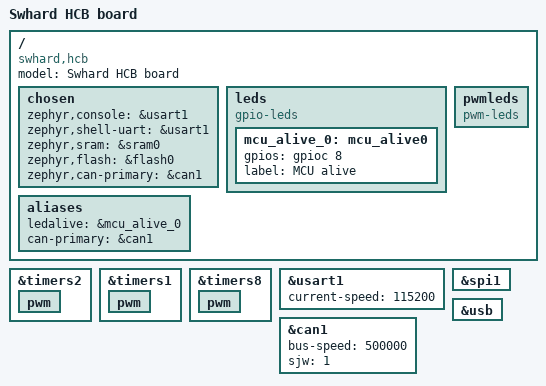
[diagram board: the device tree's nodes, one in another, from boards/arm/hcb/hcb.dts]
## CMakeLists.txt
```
# Boilerplate code, which pulls in the Zephyr build system.
cmake_minimum_required(VERSION 3.13.1)

set(BOARD_ROOT ${CMAKE_CURRENT_LIST_DIR})
set(BOARD hcb)

include($ENV{ZEPHYR_BASE}/cmake/app/boilerplate.cmake NO_POLICY_SCOPE)
project(HCB VERSION 0.1 LANGUAGES C)
message(STATUS "HCB Version: ${PROJECT_VERSION} ") 

set (COMMON_PATH ${CMAKE_CURRENT_LIST_DIR}/common)
include(${COMMON_PATH}/proto.cmake)

add_library(project_options INTERFACE)
target_compile_options(project_options INTERFACE -fdiagnostics-color=always -Wno-sign-compare -Wall -Wextra -Wnull-dereference -Wmisleading-indentation -Wduplicated-cond -Wno-unused-parameter -Werror=return-type)
target_compile_definitions(project_options  INTERFACE "HCB_FW_VERSION=\"${PROJECT_VERSION}\"")

set(CMAKE_EXPORT_COMPILE_COMMANDS ON)
# Add your source file to the "app" target. This must come after
# the boilerplate code, which defines the target.

set(APP_SRC 
src/main.c 
src/adc_subsystem.h src/adc_subsystem.c
src/usb_hcb_subsystem.h src/usb_hcb_subsystem.c
src/can_subsystem.h src/can_subsystem.c
)

target_sources(app PRIVATE ${APP_SRC})

target_link_libraries(app PUBLIC hcb_proto project_options)
```

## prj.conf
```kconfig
CONFIG_PRINTK=y
CONFIG_SHELL=y
CONFIG_KERNEL_SHELL=y
CONFIG_INIT_STACKS=y
CONFIG_BOOT_BANNER=y
CONFIG_DEVICE_SHELL=y
CONFIG_SHELL_PROMPT_UART="hcb:~$ "
CONFIG_SHELL_STACK_SIZE=1024
CONFIG_SHELL_HISTORY_BUFFER=128
CONFIG_PWM_SHELL=y
CONFIG_HEAP_MEM_POOL_SIZE=512
CONFIG_ENABLE_HID_INT_OUT_EP=y
CONFIG_USB_HID_REPORTS=2
CONFIG_HID_INTERRUPT_EP_MPS=64
CONFIG_USB_HID_POLL_INTERVAL_MS=1
CONFIG_REBOOT=y
```

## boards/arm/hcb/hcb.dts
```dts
/*
 * Copyright (c) 2017 I-SENSE group of ICCS
 *
 * SPDX-License-Identifier: Apache-2.0
 */

/dts-v1/;
#include <st/f3/stm32f303Xc.dtsi>

/ {
	model = "Swhard HCB board";
	compatible = "swhard,hcb", "st,stm32f303";

	chosen {
		zephyr,console = &usart1;
		zephyr,shell-uart = &usart1;
		zephyr,sram = &sram0;
		zephyr,flash = &flash0;
		zephyr,can-primary = &can1;
	};

	leds {
		compatible = "gpio-leds";
		mcu_alive_0: mcu_alive0 {
			gpios = <&gpioc 8 GPIO_ACTIVE_HIGH>;
			label = "MCU alive";
		};
	};

	pwmleds {
		compatible = "pwm-leds";	


	};

	aliases {
		ledalive = &mcu_alive_0;
		
		can-primary = &can1;
	};

};

&timers2 {
	status = "okay";

	pwm {
		status = "okay";
	};
};

// TIM -> PWM_DEVICE
&timers1 {
	status = "okay";

	pwm {
		status = "okay";
	};
};

// TIM -> PWM_DEVICE
&timers8 {
	status = "okay";

	pwm {
		status = "okay";
	};
};


&usart1 {
	current-speed = <115200>;
	status = "okay";
};

&spi1 {
	status = "okay";
};

&usb {
	status = "ok";
};

&can1 {
	status = "ok";
	bus-speed = <500000>;
	sjw = <1>;
};
```

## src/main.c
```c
// Set the log level to INFO
#define LOG_LEVEL LOG_LEVEL_INF
#include <logging/log.h>

// Register the module as "p" with INFO log level
LOG_MODULE_REGISTER(p, LOG_LEVEL_INF);

#include "adc_subsystem.h"

#include <drivers/can.h>
#include <drivers/gpio.h>
#include <zephyr.h>
#include <sys/printk.h>
#include <device.h>
#include <drivers/pwm.h>

#include "usb_hcb_subsystem.h"

// Define GPIO for LED
#define LED_PORT "GPIOC"
#define LED_PIN	 8

// Define minimum and maximum period for PWM
#define MIN_PERIOD_USEC (USEC_PER_SEC / 64U)
#define MAX_PERIOD_USEC USEC_PER_SEC
#define FILTER_LEN 8

// PID Controller Constants
#define Kp 0.3
#define Ki 0.7

#define K1 (Kp + Ki)
#define K2 -Kp

// Define mutexes for ADC and PID
K_MUTEX_DEFINE(adcMutex);
K_MUTEX_DEFINE(pidMutex);

// Arrays to store ADC values and set points
uint16_t adc_vals[24];
uint16_t set_points[8];
/**
 * @brief Mapping of ADC channels to axis
 * 
 * This array maps ADC channels to their corresponding axis.
 * Each row represents an ADC, and each column represents a channel.
 * The values indicate the order in which the channels are read for each ADC.
 * For example, ch2axis[0][0] represents the first channel to read for ADC 1.
 */
static const uint8_t ch2axis[AD_MAX][ADS868_CH_MAX] = {{1,2,3,4,5,6,7,0},{1,2,3,4,5,6,7,0},{1,2,3,4,5,6,7,0}};

/**
 * @brief Array indicating enabled ADC channels
 * 
 * This array indicates whether each ADC is enabled (1) or disabled (0).
 * Each element corresponds to an ADC, with 1 indicating enabled and 0 disabled.
 */
static const uint8_t enabled_adc[AD_MAX] = {1,0,1};

/**
 * @brief Function to acquire ADC values
 * 
 * This function acquires ADC values for enabled channels.
 * It uses a static array to filter ADC values over multiple samples.
 * Mutex is used to ensure thread safety.
 */
void acquire_adc()
{
	// Static variables for filtering ADC values
	static uint16_t internal_adc_vals[FILTER_LEN][24]; // Lots of SPI transactions
	static int filter_idx = 0;

	// Iterate through ADCs and channels to acquire values
	for (adc_t ad = AD_1; ad < AD_MAX; ++ad){
		if(enabled_adc[ad] == 1){
			for (channel_t ch = ADS868_CH_1; ch < ADS868_CH_MAX; ++ch) {
				int idx = (ad * 8) + ch2axis[ad][ch];
				internal_adc_vals[filter_idx][idx] = ads8668_acquire(ad, ch);
			}
		}
	}
	// Update filter index
	filter_idx++;
	if (filter_idx >= FILTER_LEN)
		filter_idx = 0;

	// Apply filter and update adc_vals array
	k_mutex_lock(&adcMutex, K_FOREVER);
	//only first ADC for the pression and third fot the current
	for (int i  = 0; i < 24 ; i++){
		int acc = 0;
		if(i < 8 || i > 15){
			for( int j = 0 ; j < FILTER_LEN ; j ++){	
				acc += internal_adc_vals[j][i]; 
				
			}
		adc_vals[i] = acc/ FILTER_LEN;
		}
	}
	k_mutex_unlock(&adcMutex);
}


/**
 * @brief Structure for PID Controller
 * 
 * This structure holds the variables required for the PID controller.
 */
typedef struct pid{
    float n_1_u;        // Previous control signal
    float n_1_error;    // Previous error
    float error;        // Current error
    float control;      // Current control signal
}pid;


/**
 * @brief PID Controller Function
 * 
 * This function implements the PID controller algorithm.
 * It calculates the control signal based on current errors and previous control signals.
 */

void PID_Controller(pid *pid_current){
	
	// Local variables for setpoints and ADC values
	uint16_t local_setpoints[8];
	uint16_t local_adcvals[24];
	
	// Copy setpoints and ADC values into local variables
	k_mutex_lock(&adcMutex, K_FOREVER);
	memcpy(local_setpoints,set_points,sizeof(set_points));
	memcpy(local_adcvals,adc_vals,sizeof(adc_vals));
	k_mutex_unlock(&adcMutex);
    
	// Iterate through ADC channels
	for(int i = 0; i < ADS868_CH_MAX; i++) {

		// Check if setpoint is below threshold
		if(local_setpoints[i] < 410) {
			pid_current[i].control = 0;
			continue;
		}
		
		//General sensor , constant value of on/off
		if(i == 6) pid_current[i].control = 5000;
		
		else{
			// Calculate error and control signal
			pid_current[i].error = local_setpoints[i] - local_adcvals[i];
			pid_current[i].control = pid_current[i].n_1_u + K1*pid_current[i].error + K2*pid_current[i].n_1_error;

			//Limite dei PWM settato 3000
			if(pid_current[i].control > 3000){
				pid_current[i].control = 3000;
			}
			if(pid_current[i].control <= 0){
				pid_current[i].control = 0;
			}
			// Update previous control signal and error
			pid_current[i].n_1_u = pid_current[i].control;
			pid_current[i].n_1_error = pid_current[i].error;
		}
		
	}

}


/**
 * @brief Set the default ADC range
 * 
 * This function sets the default range for all ADC channels.
 * It iterates through each ADC and channel, setting the range to 1.25V.
 */

void default_adc_range()
{
	for (adc_t ad = AD_1; ad < AD_MAX; ++ad) {
		for (channel_t ch = ADS868_CH_1; ch < ADS868_CH_MAX; ++ch) {
			ads8668_set_range(ad, ch, ADS868_RANGE_1_25_M);
		}
	}
}

/**
 * @brief Get the ADC values
 * 
 * This function copies ADC values to the destination buffer.
 * It locks the ADC mutex to ensure thread safety while copying.
 * 
 * @param dst Destination buffer to store ADC values
 */

void get_adc_values(uint16_t *dst)
{
	k_mutex_lock(&adcMutex, K_FOREVER);
	memcpy(dst, adc_vals, sizeof(adc_vals));
	k_mutex_unlock(&adcMutex);
}

// Declaration of static variables to store PWM devices
static const struct device *pwm_dev_1;
static const struct device *pwm_dev_2;
static const struct device *pwm_dev_8;

// Enumeration for PWM channels
typedef enum pwm_t { PWM_1, PWM_2, PWM_8, PWM_MAX } pwm_t;

// Function to get the PWM device based on the PWM channel
const struct device *get_pwm_dev(pwm_t pwm)
{
	switch (pwm) {
	case PWM_1:
		return pwm_dev_1;
	case PWM_2:
		return pwm_dev_2;
	case PWM_8:
		return pwm_dev_8;
	case PWM_MAX:
		return NULL;
	}

	return NULL;
}

// Structure to hold PWM descriptor
typedef struct pwm_descriptor_t {
	pwm_t pwm;
	uint32_t channel;
	uint32_t period;
} pwm_descriptor_t;

// Maximum number of PWM channels
#define PWM_MAX_CHANNELS 8

// PWM descriptors initialization
const pwm_descriptor_t pwm_descriptor[PWM_MAX_CHANNELS] = {
	{ PWM_2, 1, 8333 }, // SA1
	{ PWM_2, 2, 8333 }, // SA2
	{ PWM_1, 2, 8333 }, // SB1
	{ PWM_1, 1, 8333 }, // SB2
	{ PWM_8, 2, 8333 }, // SC1
	{ PWM_8, 1, 8333 }, // SC2
	{ PWM_2, 3, 8333 }, // SD1 -- 
	{ PWM_2, 4, 8333 }, // SD2
};

/**
 * @brief Initialize PWM devices
 * 
 * This function initializes the PWM devices by getting their bindings.
 * It assigns the device pointers to static variables for later use.
 */
void pwm_init()
{
	pwm_dev_1 = device_get_binding("PWM_1");
	pwm_dev_2 = device_get_binding("PWM_2");
	pwm_dev_8 = device_get_binding("PWM_8");
}

/**
 * @brief Set PWM ranges
 * 
 * This function sets the PWM ranges based on PID controller outputs.
 * It iterates through the PWM channels and sets their duty cycles accordingly.
 * Additionally, it updates the ADC values corresponding to PWM channels.
 * 
 * @param pid_current Array of PID controller structures
 */
void set_pwm_ranges(pid *pid_current)
{
	for (int i = 0; i < PWM_MAX_CHANNELS; ++i) {
		pwm_pin_set_usec(get_pwm_dev(pwm_descriptor[i].pwm), pwm_descriptor[i].channel, pwm_descriptor[i].period, (uint32_t) pid_current[i].control, 0);
		adc_vals[i+ 8] = (uint16_t)pid_current[i].control;
	}
}

/**
 * @brief Convert value from bar to bananas
 * 
 * This function converts a value from the bar scale to the bananas scale.
 * 
 * @param val Value in the bar scale
 * @return Converted value in the bananas scale
 */
uint16_t fromBartoBananas(uint32_t val){
	return (uint16_t) ((val*1600)/350) + 400;
}

/**
 * @brief Set setpoints
 * 
 * This function sets the setpoints for the PID controller.
 * It converts the values from the bar scale to the bananas scale and updates the set_points array.
 * 
 * @param vals Array of setpoints in the bar scale
 */
void set_setpoints(uint32_t *vals){
	k_mutex_lock(&adcMutex, K_FOREVER);
	for(int i = 0; i < ADS868_CH_MAX ; i++){
		set_points[i] = fromBartoBananas(vals[i]);
	}
	k_mutex_unlock(&adcMutex);
}

/**
 * @brief PID current thread
 * 
 * This thread continuously runs the PID controller algorithm.
 * It locks the PID mutex, executes the controller, sets PWM ranges, and unlocks the mutex.
 * It then waits for a specified delay before repeating the process.
 */
void pid_current_thread(){
	uint32_t target = k_uptime_get_32();
	uint32_t delay = 0;
	pid pid_current[8];
	while (1) {	
		// Current control loop and set pwm
		k_mutex_lock(&pidMutex, K_FOREVER);
		PID_Controller(pid_current);
		set_pwm_ranges(pid_current);
		k_mutex_unlock(&pidMutex);
		do {
			target += 10;
			delay = target - k_uptime_get_32();
		} while (delay > 10);
		k_sleep(K_MSEC(delay));
	}

}

/**
 * @brief Main function
 * 
 * This function is the entry point of the application.
 * It initializes necessary components, such as ADC, PWM, USB transport, and default ADC range.
 * It then enters an infinite loop where it continuously acquires ADC values, sets LED status, and sleeps for a specified delay.
 */
void main(void)
{
	const struct device *alive_dev = device_get_binding(LED_PORT);
	gpio_pin_configure(alive_dev, LED_PIN, GPIO_OUTPUT_ACTIVE);

	printk("\nHCB V:%s \n", HCB_FW_VERSION);

	adc_init();
	pwm_init();
	usb_transport_init();
	default_adc_range();

	acquire_adc();

	uint32_t target = k_uptime_get_32();
	uint32_t delay = 0;
	while (1) {	
		acquire_adc();
		do {
			target += 5;
			delay = target - k_uptime_get_32();
		} while (delay > 5);
		k_sleep(K_MSEC(delay));
		gpio_pin_set(alive_dev, LED_PIN, 1);
	}
}

/* Definition of thread stack size */
#define STACKSIZE 1024
/* scheduling priority used by each thread */
#define PRIORITY 7

/* Thread definitions */
K_THREAD_DEFINE(send_id, STACKSIZE, usb_transport_thread, NULL, NULL, NULL,
		PRIORITY, 0, 10);

K_THREAD_DEFINE(unsolicited_id, STACKSIZE, usb_unsolicited_stuff, NULL, NULL,
		NULL, PRIORITY, 0, 10);

K_THREAD_DEFINE(pid_thread, STACKSIZE, pid_current_thread, NULL, NULL,
		NULL, PRIORITY, 0, 10);
```

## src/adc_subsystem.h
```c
// Stuff to control the ADC - for now just user space
#ifndef _ADC_SUBSYSTEM_H_
#define _ADC_SUBSYSTEM_H_

#include <stdint.h>

typedef enum adc_t { AD_1, AD_2, AD_3, AD_MAX } adc_t;

typedef enum channel_t {
	ADS868_CH_1=0,
	ADS868_CH_2,
	ADS868_CH_3,
	ADS868_CH_4,
	ADS868_CH_5,
	ADS868_CH_6,
	ADS868_CH_7,
	ADS868_CH_8,
	ADS868_CH_MAX
} channel_t;

typedef enum ch_range_t {
	ADS868_RANGE_2_50_B = 0,
	ADS868_RANGE_1_25_B = 1,
	ADS868_RANGE_0_62_B = 2,
	ADS868_RANGE_0_31_B = 3,
	ADS868_RANGE_0_15_B = 11,
	ADS868_RANGE_2_50_M = 5,
	ADS868_RANGE_1_25_M = 6,
	ADS868_RANGE_0_62_M = 7,
	ADS868_RANGE_0_31_M = 15,
} ch_range_t;

void adc_init();
void adc_hw_reset();

// ADS8668 commands
int ads8668_reset_command(enum adc_t adc);
int ads8668_standby_command(enum adc_t adc);

int ads8668_acquire(adc_t adc, uint8_t ch);
int ads8668_set_range(adc_t adc, uint8_t ch, ch_range_t ch_range);

uint8_t ads8668_read_reg(adc_t adc, uint8_t reg);
int ads8668_write_reg(adc_t adc, uint8_t reg, uint8_t data);

// MAX5714 command
typedef enum max5714_output_t {
	MAX5714_DAC_A = 0x00,
	MAX5714_DAC_B = 0x01,
	MAX5714_DAC_C = 0x02,
	MAX5714_DAC_D = 0x03,
	MAX5714_DAC_ALL = 0x0f,
} max5714_output_t;

typedef enum max5714_cmd_mode_t {
	MAX5714_CMD_CODEn = 0x00,
	MAX5714_CMD_LOADn = 0x10,
	MAX5714_CMD_CODEn_LOAD_ALL = 0x20,
	MAX5714_CMD_CODEn_LOADn = 0x30,
} max5714_cmd_mode_t;

int max5714_set_value(max5714_cmd_mode_t mode, max5714_output_t output,
		      int value);
int max5714_clear();
int max5714_reset();

#endif // _ADC_SUBSYSTEM_H_
```

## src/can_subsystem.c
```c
#include "can_subsystem.h"

#include <zephyr.h>
#include <kernel.h>
#include <sys/printk.h>
#include <device.h>
#include <drivers/can.h>
#include <drivers/gpio.h>
#include <sys/byteorder.h>

// Define the stack size and priority for the receiving thread
#define RX_THREAD_STACK_SIZE	     512
#define RX_THREAD_PRIORITY	     2

// Define the stack size and priority for the state polling thread
#define STATE_POLL_THREAD_STACK_SIZE 512
#define STATE_POLL_THREAD_PRIORITY   2

// Define message IDs for LED control and counter
#define LED_MSG_ID		     0x10
#define COUNTER_MSG_ID		     0x12345

// Define commands for LED control
#define SET_LED			     1
#define RESET_LED		     0

// Define sleep time
#define SLEEP_TIME		     K_MSEC(250)

// Define the ID for the Fault Tolerance (FT) system
#define FT_ID 0x1b0

// Define a stack for the receive thread with size RX_THREAD_STACK_SIZE
K_THREAD_STACK_DEFINE(rx_thread_stack, RX_THREAD_STACK_SIZE);

// Define a stack for the poll state thread with size STATE_POLL_THREAD_STACK_SIZE
K_THREAD_STACK_DEFINE(poll_state_stack, STATE_POLL_THREAD_STACK_SIZE);

// Declare pointers to devices for CAN and LED GPIO
const struct device *can_dev;
const struct device *led_gpio_dev;

// Declare thread data structures for receive and poll state threads
struct k_thread rx_thread_data;
struct k_thread poll_state_thread_data;

// Declare work structure for receive work
struct zcan_work rx_work;

// Declare work structure for state change work
struct k_work state_change_work;

// Declare an enumeration to represent the current state of the CAN bus
enum can_state current_state;

// Declare a structure to hold the current error counts on the CAN bus
struct can_bus_err_cnt current_err_cnt;

#ifdef CANFESTIVAL_ZEPHYR_DEBUG

// Function to print the contents of a Zephyr CAN frame
static void print_frame(struct zcan_frame *frame)
{
	// Print frame ID, RTR flag, and DLC
	printk("|0x%3x|%s|%d|", frame->id, frame->rtr ? "RTR" : "   ",
	       frame->dlc);
	
    // Iterate through each byte of data in the frame
	for (int i = 0; i < CAN_MAX_DLEN; i++) {
		if (i < frame->dlc) {

			// Print data byte in hexadecimal format
			printk(" 0x%02x", frame->data[i]);
		} else {
			// If data length is less than the maximum, pad with spaces
			printk("     ");
		}
	}
    // End the line
	printk("|\n");
}
#endif

// Callback function invoked upon transmission error interrupt
void tx_irq_callback(uint32_t error_flags, void *arg)
{   
	// Cast arg to a character pointer representing the sender
	char *sender = (char *)arg;
    // If error flags are non-zero, print error details
	if (error_flags) {
		printk("Callback! error-code: %d\nSender: %s\n", error_flags,
		       sender);
	}
}

// Define a mutex for protecting access to force and torque arrays
K_MUTEX_DEFINE(ftMutex);

// Arrays to store force and torque values
static int32_t forces[3];
static int32_t torques[3];

/**
 * @brief Get the adc values object
 * 
 * @param dst   Destination array to store force and torque values
 */
void get_ft_values(int32_t *dst)
{
	// Lock the mutex to prevent concurrent access to force and torque arrays
	k_mutex_lock(&ftMutex, K_FOREVER);

	// Copy force and torque arrays into destination array
	memcpy(dst, forces, sizeof(forces));
	memcpy(dst+3, torques, sizeof(torques));

	// Unlock the mutex to allow other threads to access force and torque arrays
	k_mutex_unlock(&ftMutex);
}

/**
 * @brief Callback function to receive and update force and torque values
 * 
 * @param frame Pointer to the received CAN frame
 * @param unused Unused argument
 */
void receive_change_led(struct zcan_frame *frame, void *unused)
{
	ARG_UNUSED(unused);
    
	// Iterate over the array indices to check if the received frame corresponds to force or torque data
	for (int i = 1; i < 4; ++i)
	{
		// Check if the frame ID matches the expected ID for force or torque data
		if (frame->id == (FT_ID + i)) {

			// Lock the mutex to prevent concurrent access to force and torque arrays
			k_mutex_lock(&ftMutex, K_FOREVER);

			// Extract force and torque values from the received frame and store them in the respective arrays
			uint32_t f = frame->data_32[0];
			forces[i - 1] = (int32_t)__bswap_32(f);
			uint32_t t = frame->data_32[1];
			torques[i - 1] = (int32_t)__bswap_32(t);

			// Unlock the mutex to allow other threads to access force and torque arrays
			k_mutex_unlock(&ftMutex);
		}
	}

// Optional debug printing if CANFESTIVAL_ZEPHYR_DEBUG is defined
#ifdef CANFESTIVAL_ZEPHYR_DEBUG
	printk(" CAN_RECEIVE: ");
	print_frame(frame);
#endif
}

/**
 * @brief Converts a CAN state enum value to its string representation.
 * 
 * @param state The CAN state enum value to convert.
 * @return A string representation of the CAN state.
 */
char *state_to_str(enum can_state state)
{
	switch (state) {
	case CAN_ERROR_ACTIVE:
		return "error-active";
	case CAN_ERROR_PASSIVE:
		return "error-passive";
	case CAN_BUS_OFF:
		return "bus-off";
	default:
		return "unknown";
	}
}

/**
 * @brief Thread function to continuously poll the CAN bus state and error counts.
 * 
 * @param unused1 Unused parameter (required by Zephyr thread API).
 * @param unused2 Unused parameter (required by Zephyr thread API).
 * @param unused3 Unused parameter (required by Zephyr thread API).
 */
void poll_state_thread(void *unused1, void *unused2, void *unused3)
{   
	// Initialize error count structures
	struct can_bus_err_cnt err_cnt = { 0, 0 };
	struct can_bus_err_cnt err_cnt_prev = { 0, 0 };

	// Initialize previous state to error active
	enum can_state state_prev = CAN_ERROR_ACTIVE;

	// Variable to hold current CAN state
	enum can_state state;
    
	// Continuous loop to poll CAN state and error counts
	while (1) {

		// Get current CAN state and error counts
		state = can_get_state(can_dev, &err_cnt);

		// Check if there's a change in state or error counts
		if (err_cnt.tx_err_cnt != err_cnt_prev.tx_err_cnt ||
		    err_cnt.rx_err_cnt != err_cnt_prev.rx_err_cnt ||
		    state_prev != state) {
			// Update previous error counts and state
			err_cnt_prev.tx_err_cnt = err_cnt.tx_err_cnt;
			err_cnt_prev.rx_err_cnt = err_cnt.rx_err_cnt;
			state_prev = state;

			// Print current state and error counts
			printk("state: %s\n"
			       "rx error count: %d\n"
			       "tx error count: %d\n",
			       state_to_str(state), err_cnt.rx_err_cnt,
			       err_cnt.tx_err_cnt);
		} else {

			// Sleep for a short duration to avoid continuous polling
			k_sleep(K_MSEC(100));
		}
	}
}

/**
 * @brief Handler function for state change work.
 * 
 * @param work Pointer to the work item.
 */
void state_change_work_handler(struct k_work *work)
{
	// Print current state and error counts
	printk("State Change ISR\nstate: %s\n"
	       "rx error count: %d\n"
	       "tx error count: %d\n",
	       state_to_str(current_state), current_err_cnt.rx_err_cnt,
	       current_err_cnt.tx_err_cnt);

// Perform recovery from bus-off state if auto recovery is not enabled
#ifndef CONFIG_CAN_AUTO_BUS_OFF_RECOVERY
	if (current_state == CAN_BUS_OFF) {
		printk("Recover from bus-off\n");

        // Attempt to recover from bus-off state
		if (can_recover(can_dev, K_MSEC(100) != 0)) {
			printk("Recovery timed out\n");
		}
	}
#endif /* CONFIG_CAN_AUTO_BUS_OFF_RECOVERY */
}

/**
 * @brief Interrupt service routine for CAN state change.
 * 
 * @param state The new CAN state.
 * @param err_cnt Error counts for the CAN bus.
 */
void state_change_isr(enum can_state state, struct can_bus_err_cnt err_cnt)
{
	// Update current state and error counts
	current_state = state;
	current_err_cnt = err_cnt;

	// Submit state change work for handling
	k_work_submit(&state_change_work);
}

/**
 * @brief Main thread for handling CAN communication and LED change requests.
 * 
 * @param _1 Unused parameter (required by Zephyr thread API).
 * @param _2 Unused parameter (required by Zephyr thread API).
 * @param _3 Unused parameter (required by Zephyr thread API).
 */
void main_can_ati_thread(void *_1, void *_2, void *_3)
{
	// Define a CAN filter for LED change messages
	static const struct zcan_filter my_filter = {
		.id_type = CAN_STANDARD_IDENTIFIER,
		.rtr = CAN_DATAFRAME,
		.id = 0x1,
		.rtr_mask = 0,
		.id_mask = 0x0
	};
    // Define a CAN frame for requesting LED changes
	struct zcan_frame req_long_data_frame = {
		.id_type = CAN_STANDARD_IDENTIFIER,
		.rtr = CAN_DATAFRAME,
		.id = FT_ID,
		.dlc = 1
	};
    // Variable to toggle LED change data
    uint8_t toggle = 1;
    
    // Counter for LED change requests
    uint16_t counter = 0;
    
    // Thread IDs for polling state and receiving CAN frames
    k_tid_t rx_tid, get_state_tid;
    
    // Return value for function calls
    int ret;

    // Get the CAN device
    can_dev = device_get_binding(DT_CHOSEN_ZEPHYR_CAN_PRIMARY_LABEL);

    // Check if CAN device is found
    if (!can_dev) {
        printk("CAN: Device driver not found.\n");
        return;
    }

    // Initialize state change work handler
    k_work_init(&state_change_work, state_change_work_handler);

    // Attach a filter for receiving LED change messages
    ret = can_attach_workq(can_dev, &k_sys_work_q, &rx_work,
                           receive_change_led, NULL, &my_filter);
    if (ret == CAN_NO_FREE_FILTER) {
        printk("Error, no filter available!\n");
        return;
    }

    // Create a thread for polling CAN bus state
	printk("Change LED filter ID: %d\n", ret);
	get_state_tid =
		k_thread_create(&poll_state_thread_data, poll_state_stack,
				K_THREAD_STACK_SIZEOF(poll_state_stack),
				poll_state_thread, NULL, NULL, NULL,
				STATE_POLL_THREAD_PRIORITY, 0, K_NO_WAIT);
	if (!get_state_tid) {
		printk("ERROR spawning poll_state_thread\n");
	}

    // Register CAN state change ISR
    can_register_state_change_isr(can_dev, state_change_isr);

    // Print initialization completion message
    printk("Finished init.\n");

    // Main loop for sending LED change requests
    while (1) {
        // Set LED change request data
        req_long_data_frame.data[0] = 0x01;
        
        // Send LED change request
        can_send(can_dev, &req_long_data_frame, K_FOREVER,
                 tx_irq_callback, "LED change");
        
        // Sleep for a defined duration
        k_sleep(SLEEP_TIME);
    }
}

// Thread Definition

// Define stack size and priority for main CAN ATI thread
#define CANATI_STACK_SIZE 512
#define CANATI_PRIORITY	  5

// Define main CAN ATI thread
K_THREAD_DEFINE(CANATI, CANATI_STACK_SIZE, main_can_ati_thread, NULL, NULL,
                NULL, CANATI_PRIORITY, 0, 0);
```

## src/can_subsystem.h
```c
#ifndef CAN_SUBSYSTEM_H_
#define CAN_SUBSYSTEM_H_



#endif // CAN_SUBSYSTEM_H_
```

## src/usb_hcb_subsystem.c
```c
/*
 * Copyright (c) 2019 Intel Corporation
 *
 * SPDX-License-Identifier: Apache-2.0
 */

#define LOG_LEVEL LOG_LEVEL_INF
#include <logging/log.h>

LOG_MODULE_REGISTER(usb_transport, LOG_LEVEL_INF);

#include <zephyr.h>

#include <usb/usb_device.h>
#include <usb/class/usb_hid.h>
#include <drivers/gpio.h>
#include <sys/crc.h>

// SHELL STUFF
#include <shell/shell.h>
#include <stdlib.h>

#include "usb_hcb_subsystem.h"

typedef struct msg_data_t {
	void *fifo_reserved; /* 1st word reserved for use by fifo */
	hcb_protocol_t msg;
} msg_data_t;

// FIFO DEFINITION
K_FIFO_DEFINE(trasmission_fifo);
// SEMAPHORE
K_SEM_DEFINE(my_sem, 0, 1);

/* callback function list */
static void usb_transport_host_ready(const struct device *dev);

void int_out_ready_cb(const struct device *dev);

int usb_transport_send_reply(hcb_protocol_t *proto);

static const struct hid_ops usb_transport_callbacks = {
	.int_in_ready = usb_transport_host_ready,
	.int_out_ready = int_out_ready_cb,
};

/* create an HID report descriptor with input and output reports */
static const uint8_t usb_transport_hid_report_desc[] = {
	0x06, 0x00, 0xFF, // (GLOBAL) USAGE_PAGE         0xFF00 Vendor-defined
	0x09, 0x01, //   (LOCAL)  USAGE              0xFF000001
	0xA1, 0x01, // (MAIN)   COLLECTION         0x01 Application (Usage=0x0: Page=, Usage=, Type=) <-- Warning: USAGE type should be CA (Application)
	0x15, 0x00, //   (GLOBAL) LOGICAL_MINIMUM    0x00 (0) <-- Redundant: LOGICAL_MINIMUM is already 0
	0x26, 0xFF, 0x00, //   (GLOBAL) LOGICAL_MAXIMUM    0x00FF (255)
	0x75, 0x08, //   (GLOBAL) REPORT_SIZE        0x08 (8) Number of bits per field
	0x85, 0x01, //   (GLOBAL) REPORT_ID          0x01 (1)
	0x95, 0x50, //   (GLOBAL) REPORT_COUNT       0x40 (64) Number of fields
	0x09, 0x01, //   (LOCAL)  USAGE              0xFF000001
	0x81, 0x02, //   (MAIN)   INPUT              0x00000002 (64 fields x 8 bits) 0=Data 1=Variable 0=Absolute 0=NoWrap 0=Linear 0=PrefState 0=NoNull 0=NonVolatile 0=Bitmap
	0x85, 0x02, //   (GLOBAL) REPORT_ID          0x02 (2)
	0x09, 0x01, //   (LOCAL)  USAGE              0xFF000001
	0x95, 0x20, //   (GLOBAL) REPORT_COUNT       0x20 (32) Number of fields
	0x91, 0x02, //   (MAIN)   OUTPUT             0x00000002 (64 fields x 8 bits) 0=Data 1=Variable 0=Absolute 0=NoWrap 0=Linear 0=PrefState 0=NoNull 0=NonVolatile 0=Bitmap
	0xC0, // (MAIN)   END_COLLECTION     Application
};

static const struct device *hid_device;
static hcb_protocol_t hb1 = {};

// PROTOTYPES
int usb_transfer_msg(hcb_protocol_t *proto);

//
int send_msg_hello_reply()
{
	hb1.header.report_id = HCB_REPORT_ID_IN_REPLY;
	hb1.header.message_id = HCB_ID_HELLO_REPLY;
	hb1.header.crc = 0;
	hb1.header.byte_count = sizeof(hcb_msg_hello_reply_t);

	hb1.hello_reply.ver = HCB_PROTOCOL_VER;

	hb1.header.crc = crc8_ccitt(0x0, hb1.raw, hb1.header.byte_count);

	LOG_ERR("send_msg_hello_reply !");

	int ret = usb_transport_send_reply(&hb1);

	if (ret) {
		LOG_ERR("send_msg_hello_reply error %d", ret);
	}
	return ret;
}

int send_msg_adc()
{
	hb1.header.report_id = HCB_REPORT_ID_IN_REPLY;
	hb1.header.message_id = HCB_ID_ADC;
	hb1.header.crc = 0;
	hb1.header.byte_count = sizeof(hcb_msg_adc_t);

	for (int i = 0; i < 24; ++i) {
		hb1.adc.val[i] = i;
	}

	hb1.header.crc = crc8_ccitt(0x0, hb1.raw, hb1.header.byte_count);

	int ret = usb_transport_send_reply(&hb1);
	if (ret) {
		LOG_ERR("send_msg_adc error %d", ret);
	}

	return ret;
}

int send_adc_values()
{
	hb1.header.report_id = HCB_REPORT_ID_IN_UNSOLICITED;
	hb1.header.message_id = HCB_ID_ADC;
	hb1.header.crc = 0;
	hb1.header.byte_count = sizeof(hcb_msg_adc_t);

	get_adc_values(hb1.adc.val);

	hb1.header.crc = crc8_ccitt(0x0, hb1.raw, hb1.header.byte_count);

	int ret = usb_transport_send_reply(&hb1);
	return ret;
}

static void status_cb(enum usb_dc_status_code status, const uint8_t *param)
{
	switch (status) {
	case USB_DC_CONFIGURED:
		LOG_INF(" #USB_DC_CONFIGURED");
		k_sem_give(&my_sem);
		break;
	default:
		LOG_ERR("status CB %u", status);
		break;
	}
}

int send_ati_values()
{
	hb1.header.report_id = HCB_REPORT_ID_IN_UNSOLICITED;
	hb1.header.message_id = HCB_ID_FT;
	hb1.header.crc = 0;
	hb1.header.byte_count = sizeof(hcb_msg_adc_t);

	get_ft_values(hb1.ft.val);

	hb1.header.crc = crc8_ccitt(0x0, hb1.raw, hb1.header.byte_count);

	int ret = usb_transport_send_reply(&hb1);
	return ret;
}

/**
 * @brief
 *
 * @return int
 */
int usb_transport_init()
{
	const struct device *adc_rst = device_get_binding("GPIOA");
	int res = gpio_pin_configure(adc_rst, 10, GPIO_OUTPUT_ACTIVE);
	res = gpio_pin_set(adc_rst, 10, 1);

	int ret;

	hid_device = device_get_binding("HID_0");

	if (hid_device == NULL) {
		LOG_ERR("USB HID Device not found");
		return -ENODEV;
	}

	/* register a HID device and the callback functions */
	usb_hid_register_device(hid_device, usb_transport_hid_report_desc,
				sizeof(usb_transport_hid_report_desc),
				&usb_transport_callbacks);

	ret = usb_enable(status_cb);
	if (ret != 0) {
		LOG_ERR("Failed to enable USB");
		return -EIO;
	}
	/* initialize USB interface and HID class */
	return usb_hid_init(hid_device);
}

/**
 * @brief enqueue message for the
 *
 * @param proto
 * @return int
 */
int usb_transfer_msg(hcb_protocol_t *proto)
{
	size_t size = sizeof(struct msg_data_t);

	msg_data_t *mem_ptr = (msg_data_t *)k_malloc(size);
	__ASSERT_NO_MSG(mem_ptr != 0);

	memcpy(&mem_ptr->msg, proto, size);

	k_fifo_put(&trasmission_fifo, mem_ptr);
	return 0;
}

/**
 * @brief
 *
 */
void usb_transport_thread(void)
{
	while (1) {
		struct msg_data_t *rx_data =
			k_fifo_get(&trasmission_fifo, K_FOREVER);

		if (rx_data == NULL) {
			LOG_ERR(" Failed get");
			continue;
		}

		hcb_protocol_t *buf = &rx_data->msg;

		uint8_t message_id = ((hcb_proto_header_t *)buf)->message_id;

		// TODO add CRC check
		switch (message_id) {
		case HCB_ID_COMMAND: {
			uint32_t command = ((hcb_protocol_t *)buf)->cmd.command;
			if (command == HCB_CMD_HELLO) {
				send_msg_hello_reply();
			}
			if (command == HCB_CMD_READ_ADC) {
				send_msg_adc();
			}
		} break;
		case HCB_ID_UNSOLICITED_TIME: {
			send_adc_values();
		} break;
		case HCB_ID_UNSOLICITED_TIME_2: {
			send_ati_values();
		} break;
		case HCB_ID_SET_POINT: {
			set_setpoints(buf->set.val);
		} break;
		default:
			LOG_ERR(" RECEIVED other %d\n", message_id);
			break;
		}

		k_free(rx_data);
	}
}

void usb_unsolicited_stuff(void)
{
	static hcb_protocol_t buf = {};
	while (1) {
		buf.header.report_id = 2;
		buf.header.message_id = HCB_ID_UNSOLICITED_TIME;
		buf.header.crc = 0;
		buf.header.byte_count = sizeof(hcb_proto_header_t);

		int ret = usb_transfer_msg(&buf);
		if (ret) {
			LOG_ERR("usb_transfer_msg error %d", ret);
		}
		k_sleep(K_MSEC(100));
	
		buf.header.report_id = 2;
		buf.header.message_id = HCB_ID_UNSOLICITED_TIME_2;
		buf.header.crc = 0;
		buf.header.byte_count = sizeof(hcb_proto_header_t);
		 ret = usb_transfer_msg(&buf);
		if (ret) {
			LOG_ERR("usb_transfer_msg error %d", ret);
		}
		k_sleep(K_MSEC(100));
	}
}

int usb_transport_send_reply(hcb_protocol_t *proto)
{
	uint32_t written = 0;

	if (k_sem_take(&my_sem, K_USEC(333)) != 0) {
		return -1;
	}

	// dump_buf("Send:", proto->raw, proto->header.byte_count);
	/* send reply in one or more HID reports */
	// ************
	// 0x41 because windows drops report of the wrong size.
	// output reports are of the size of 0x40 plus the report number
	int ret = hid_int_ep_write(hid_device, (uint8_t *)proto->raw, proto->header.byte_count,
				   &written);

	if (ret) {
		LOG_INF("usb_write failed with error %d", ret);
	}

	if (written != proto->header.byte_count) {
		/* usb_write is expected to send all data */
		LOG_DBG("usb_write: requested %u sent %u",
			proto->header.byte_count, written);
		//ret = -EIO;
	}
	return ret;
}

static void usb_transport_host_ready(const struct device *dev)
{
	// Give the semaphore back to reenable transmission
	k_sem_give(&my_sem);
}

static uint8_t buf[128];

void int_out_ready_cb(const struct device *dev)
{
	uint32_t len = 0;
	hid_int_ep_read(hid_device, buf, 64, &len);
	usb_transfer_msg((hcb_protocol_t *)buf);
}
```

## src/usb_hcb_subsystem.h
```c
/*
 * Copyright (c) 2019 Intel Corporation
 *
 * SPDX-License-Identifier: Apache-2.0
 */

#ifndef TUNING_USB_TRANSPORT_H
#define TUNING_USB_TRANSPORT_H

#include "hcb_protocol.h"

typedef void (*usb_transport_receive_callback_t)(uint8_t *data, uint32_t len);

int usb_transport_init();
int usb_transport_send_reply(hcb_protocol_t *proto);
void usb_transport_thread(void);
void usb_unsolicited_stuff(void);
int send_msg_test();

#endif /* TUNING_USB_TRANSPORT_H */
```
